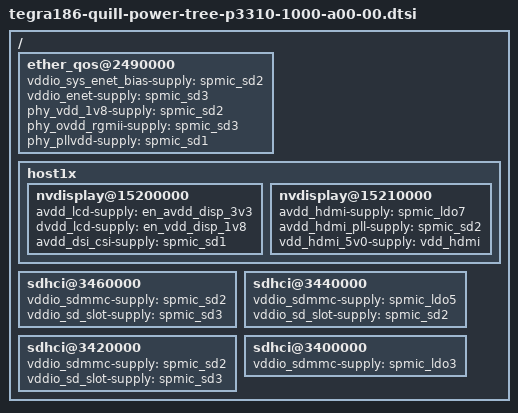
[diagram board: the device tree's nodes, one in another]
/*
 * Copyright (c) 2015, NVIDIA CORPORATION.  All rights reserved.
 *
 * This program is free software; you can redistribute it and/or modify
 * it under the terms of the GNU General Public License as published by
 * the Free Software Foundation; either version 2 of the License, or
 * (at your option) any later version.
 *
 * This program is distributed in the hope that it will be useful, but WITHOUT
 * ANY WARRANTY; without even the implied warranty of MERCHANTABILITY or
 * FITNESS FOR A PARTICULAR PURPOSE.  See the GNU General Public License for
 * more details.
 *
 */

#include "tegra186-quill-spmic-p3310-1000-a00-00.dtsi"
#include "tegra186-cvb-prod-p2597-b00-p3310-1000-a00-00.dtsi"

/ {

	ether_qos@2490000 {
		vddio_sys_enet_bias-supply = <&spmic_sd2>;
		vddio_enet-supply = <&spmic_sd3>;
		phy_vdd_1v8-supply = <&spmic_sd2>;
		phy_ovdd_rgmii-supply = <&spmic_sd3>;
		phy_pllvdd-supply = <&spmic_sd1>;
	};

	host1x {
		nvdisplay@15200000 {
			avdd_lcd-supply = <&en_avdd_disp_3v3>;
			dvdd_lcd-supply = <&en_vdd_disp_1v8>;
			avdd_dsi_csi-supply = <&spmic_sd1>;
		};
                nvdisplay@15210000 {
                        avdd_hdmi-supply = <&spmic_ldo7>;
                        avdd_hdmi_pll-supply = <&spmic_sd2>;
                        vdd_hdmi_5v0-supply = <&vdd_hdmi>;
                };
        };

	sdhci@3460000 {
		vddio_sdmmc-supply = <&spmic_sd2>;
		vddio_sd_slot-supply = <&spmic_sd3>;
	};

	sdhci@3440000 {
		vddio_sdmmc-supply = <&spmic_ldo5>;
		vddio_sd_slot-supply = <&spmic_sd2>;
	};

	sdhci@3420000 {
		vddio_sdmmc-supply = <&spmic_sd2>;
		vddio_sd_slot-supply = <&spmic_sd3>;
	};

	sdhci@3400000 {
		vddio_sdmmc-supply = <&spmic_ldo3>;
	};
};
